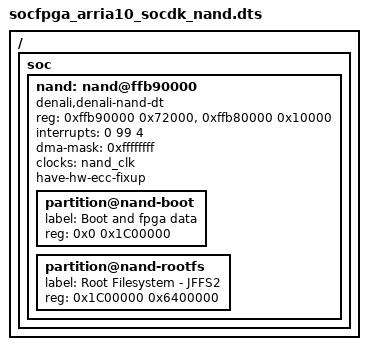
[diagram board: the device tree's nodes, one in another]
/*
 * Copyright (C) 2015 Altera Corporation. All rights reserved.
 *
 * This program is free software; you can redistribute it and/or modify
 * it under the terms and conditions of the GNU General Public License,
 * version 2, as published by the Free Software Foundation.
 *
 * This program is distributed in the hope it will be useful, but WITHOUT
 * ANY WARRANTY; without even the implied warranty of MERCHANTABILITY or
 * FITNESS FOR A PARTICULAR PURPOSE.  See the GNU General Public License for
 * more details.
 *
 * You should have received a copy of the GNU General Public License along with
 * this program.  If not, see <http://www.gnu.org/licenses/>.
 */

/dts-v1/;
#include "socfpga_arria10_socdk.dtsi"

/ {
	soc {
		nand: nand@ffb90000 {
			#address-cells = <1>;
			#size-cells = <1>;
			compatible = "denali,denali-nand-dt";
			reg = <0xffb90000 0x72000>, <0xffb80000 0x10000>;
			reg-names = "nand_data", "denali_reg";
			interrupts = <0 99 4>;
			dma-mask = <0xffffffff>;
			clocks = <&nand_clk>;
			have-hw-ecc-fixup;
			status = "okay";

			partition@nand-boot {
				label = "Boot and fpga data";
				reg = <0x0 0x1C00000>;
			};
			partition@nand-rootfs {
				label = "Root Filesystem - JFFS2";
				reg = <0x1C00000 0x6400000>;
			};
		};
	};
};
